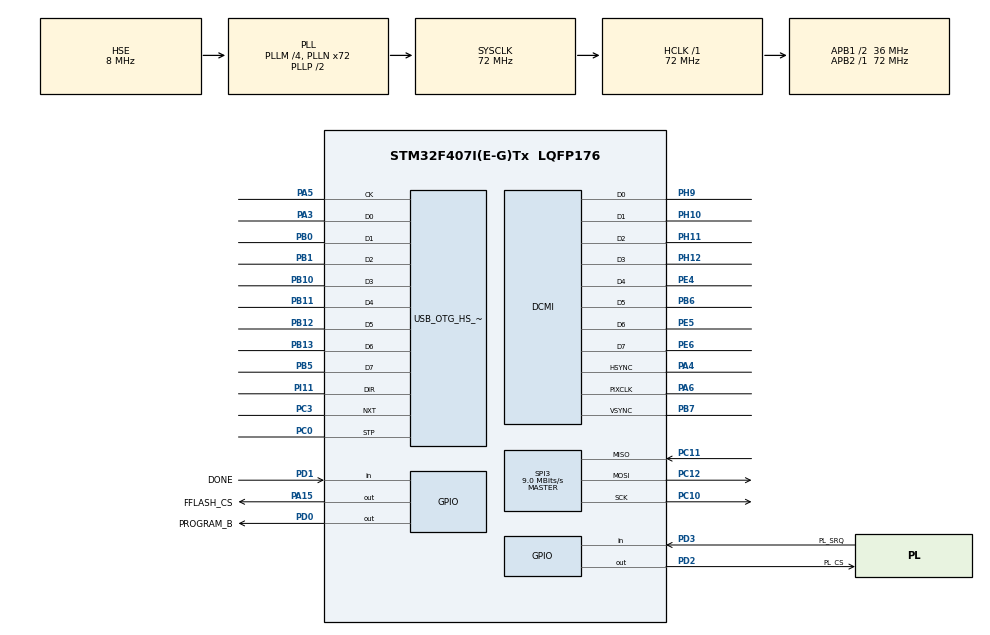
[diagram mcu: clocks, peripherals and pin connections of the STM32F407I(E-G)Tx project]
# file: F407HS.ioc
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DCMI.HSPolarity=DCMI_HSPOLARITY_HIGH
DCMI.JPEGMode=DCMI_JPEG_ENABLE
DCMI.PCKPolarity=DCMI_PCKPOLARITY_RISING
DCMI.VSPolarity=DCMI_VSPOLARITY_HIGH
Dma.DCMI.0.Direction=DMA_PERIPH_TO_MEMORY
Dma.DCMI.0.FIFOMode=DMA_FIFOMODE_DISABLE
Dma.DCMI.0.Instance=DMA2_Stream1
Dma.DCMI.0.MemDataAlignment=DMA_MDATAALIGN_WORD
Dma.DCMI.0.MemInc=DMA_MINC_ENABLE
Dma.DCMI.0.Mode=DMA_NORMAL
Dma.DCMI.0.PeriphDataAlignment=DMA_PDATAALIGN_WORD
Dma.DCMI.0.PeriphInc=DMA_PINC_DISABLE
Dma.DCMI.0.Priority=DMA_PRIORITY_LOW
Dma.Request0=DCMI
Mcu.Family=STM32F4
Mcu.Name=STM32F407I(E-G)Tx
Mcu.Package=LQFP176
NVIC.DMA2_Stream1_IRQn=true\:0\:0\:false\:false\:true\:false\:true
NVIC.OTG_HS_EP1_IN_IRQn=true\:0\:0\:false\:false\:true\:true\:true
NVIC.OTG_HS_EP1_OUT_IRQn=true\:0\:0\:false\:false\:true\:true\:true
NVIC.OTG_HS_IRQn=true\:0\:0\:false\:false\:true\:true\:true
NVIC.PriorityGroup=NVIC_PRIORITYGROUP_4
PA13.Mode=Serial_Wire
PA13.Signal=SYS_JTMS-SWDIO
PA14.Mode=Serial_Wire
PA14.Signal=SYS_JTCK-SWCLK
PA15.GPIO_Label=FFLASH_CS
PA15.GPIO_Speed=GPIO_SPEED_FREQ_HIGH
PA15.PinState=GPIO_PIN_SET
PA15.Signal=GPIO_Output
PA3.Mode=Device_HS
PA3.Signal=USB_OTG_HS_ULPI_D0
PA4.GPIO_PuPd=GPIO_PULLUP
PA4.GPIO_Speed=GPIO_SPEED_FREQ_HIGH
PA4.Mode=Slave_8_bits_External_Synchro
PA4.Signal=DCMI_HSYNC
PA5.Mode=Device_HS
PA5.Signal=USB_OTG_HS_ULPI_CK
PA6.GPIO_PuPd=GPIO_PULLUP
PA6.GPIO_Speed=GPIO_SPEED_FREQ_HIGH
PA6.Mode=Slave_8_bits_External_Synchro
PA6.Signal=DCMI_PIXCLK
PB0.Mode=Device_HS
PB0.Signal=USB_OTG_HS_ULPI_D1
PB1.Mode=Device_HS
PB1.Signal=USB_OTG_HS_ULPI_D2
PB10.Mode=Device_HS
PB10.Signal=USB_OTG_HS_ULPI_D3
PB11.Mode=Device_HS
PB11.Signal=USB_OTG_HS_ULPI_D4
PB12.Mode=Device_HS
PB12.Signal=USB_OTG_HS_ULPI_D5
PB13.Mode=Device_HS
PB13.Signal=USB_OTG_HS_ULPI_D6
PB5.Mode=Device_HS
PB5.Signal=USB_OTG_HS_ULPI_D7
PB6.GPIO_Speed=GPIO_SPEED_FREQ_HIGH
PB6.Mode=Slave_8_bits_External_Synchro
PB6.Signal=DCMI_D5
PB7.GPIO_PuPd=GPIO_PULLUP
PB7.GPIO_Speed=GPIO_SPEED_FREQ_HIGH
PB7.Mode=Slave_8_bits_External_Synchro
PB7.Signal=DCMI_VSYNC
PC0.Mode=Device_HS
PC0.Signal=USB_OTG_HS_ULPI_STP
PC10.Mode=Full_Duplex_Master
PC10.Signal=SPI3_SCK
PC11.Mode=Full_Duplex_Master
PC11.Signal=SPI3_MISO
PC12.Mode=Full_Duplex_Master
PC12.Signal=SPI3_MOSI
PC3.Mode=Device_HS
PC3.Signal=USB_OTG_HS_ULPI_NXT
PD0.GPIO_Label=PROGRAM_B
PD0.PinState=GPIO_PIN_RESET
PD0.Signal=GPIO_Output
PD1.GPIO_Label=DONE
PD1.GPIO_PuPd=GPIO_PULLDOWN
PD1.Signal=GPIO_Input
PD2.GPIO_Label=PL_CS
PD2.GPIO_Speed=GPIO_SPEED_FREQ_HIGH
PD2.PinState=GPIO_PIN_SET
PD2.Signal=GPIO_Output
PD3.GPIO_Label=PL_SRQ
PD3.GPIO_PuPd=GPIO_PULLUP
PD3.Signal=GPIO_Input
PE4.GPIO_Speed=GPIO_SPEED_FREQ_HIGH
PE4.Mode=Slave_8_bits_External_Synchro
PE4.Signal=DCMI_D4
PE5.GPIO_Speed=GPIO_SPEED_FREQ_HIGH
PE5.Mode=Slave_8_bits_External_Synchro
PE5.Signal=DCMI_D6
PE6.GPIO_Speed=GPIO_SPEED_FREQ_HIGH
PE6.Mode=Slave_8_bits_External_Synchro
PE6.Signal=DCMI_D7
PH0-OSC_IN.Mode=HSE-External-Oscillator
PH0-OSC_IN.Signal=RCC_OSC_IN
PH1-OSC_OUT.Mode=HSE-External-Oscillator
PH1-OSC_OUT.Signal=RCC_OSC_OUT
PH10.GPIO_Speed=GPIO_SPEED_FREQ_HIGH
PH10.Mode=Slave_8_bits_External_Synchro
PH10.Signal=DCMI_D1
PH11.GPIO_Speed=GPIO_SPEED_FREQ_HIGH
PH11.Mode=Slave_8_bits_External_Synchro
PH11.Signal=DCMI_D2
PH12.GPIO_Speed=GPIO_SPEED_FREQ_HIGH
PH12.Mode=Slave_8_bits_External_Synchro
PH12.Signal=DCMI_D3
PH9.GPIO_Speed=GPIO_SPEED_FREQ_HIGH
PH9.Mode=Slave_8_bits_External_Synchro
PH9.Signal=DCMI_D0
PI11.Mode=Device_HS
PI11.Signal=USB_OTG_HS_ULPI_DIR
ProjectManager.HeapSize=0x2000
ProjectManager.StackSize=0x400
ProjectManager.TargetToolchain=EWARM V8.32
RCC.48MHZClocksFreq_Value=48000000
RCC.AHBFreq_Value=72000000
RCC.APB1CLKDivider=RCC_HCLK_DIV2
RCC.APB1Freq_Value=36000000
RCC.APB1TimFreq_Value=72000000
RCC.APB2Freq_Value=72000000
RCC.APB2TimFreq_Value=72000000
RCC.CortexFreq_Value=72000000
RCC.HCLKFreq_Value=72000000
RCC.HSE_VALUE=8000000
RCC.HSI_VALUE=16000000
RCC.LSE_VALUE=32768
RCC.PLLM=4
RCC.PLLN=72
RCC.PLLQ=3
RCC.PLLSourceVirtual=RCC_PLLSOURCE_HSE
RCC.SYSCLKFreq_VALUE=72000000
RCC.SYSCLKSource=RCC_SYSCLKSOURCE_PLLCLK
RCC.VCOOutputFreq_Value=144000000
SPI3.BaudRatePrescaler=SPI_BAUDRATEPRESCALER_4
SPI3.CalculateBaudRate=9.0 MBits/s
SPI3.Direction=SPI_DIRECTION_2LINES
SPI3.Mode=SPI_MODE_MASTER
SPI3.VirtualType=VM_MASTER
USB_DEVICE.CLASS_NAME_HS=CDC
USB_DEVICE.VirtualMode-CDC_HS=Cdc
USB_DEVICE.VirtualModeHS=Cdc_HS
USB_OTG_HS.VirtualMode-Device_HS=Device_HS
VP_USB_DEVICE_VS_USB_DEVICE_CDC_HS.Mode=CDC_HS
board=custom

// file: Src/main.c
/* USER CODE BEGIN Header */
/**
  ******************************************************************************
  * @file           : main.c
  * @brief          : Main program body
  ******************************************************************************
  * @attention
  *
  * <h2><center>&copy; Copyright (c) 2020 STMicroelectronics.
  * All rights reserved.</center></h2>
  *
  * This software component is licensed by ST under Ultimate Liberty license
  * SLA0044, the "License"; You may not use this file except in compliance with
  * the License. You may obtain a copy of the License at:
  *                             www.st.com/SLA0044
  *
  ******************************************************************************
  */
/* USER CODE END Header */

#include "main.h"
#include "usb_device.h"

/* USER CODE BEGIN Includes */
#include "usb_tmc.h"
/* USER CODE END Includes */

DCMI_HandleTypeDef hdcmi;
DMA_HandleTypeDef hdma_dcmi;

SPI_HandleTypeDef hspi3;

void SystemClock_Config(void);
static void MX_GPIO_Init(void);
static void MX_SPI3_Init(void);
static void MX_DMA_Init(void);
static void MX_DCMI_Init(void);

int main(void)
{

  /* MCU Configuration--------------------------------------------------------*/

  /* Reset of all peripherals, Initializes the Flash interface and the Systick. */
  HAL_Init();

  /* Configure the system clock */
  SystemClock_Config();

  /* USER CODE BEGIN SysInit */
  USB_TMC_init();
  /* USER CODE END SysInit */

  /* Initialize all configured peripherals */
  MX_GPIO_Init();
  MX_USB_DEVICE_Init();
  MX_SPI3_Init();
  MX_DMA_Init();
  MX_DCMI_Init();

  /* Infinite loop */
  while (1)
  {

    /* USER CODE BEGIN 3 */
    USB_TMC_Process();
  }
  /* USER CODE END 3 */
}

void SystemClock_Config(void)
{
  RCC_OscInitTypeDef RCC_OscInitStruct = {0};
  RCC_ClkInitTypeDef RCC_ClkInitStruct = {0};

  /** Configure the main internal regulator output voltage
  */
  __HAL_RCC_PWR_CLK_ENABLE();
  __HAL_PWR_VOLTAGESCALING_CONFIG(PWR_REGULATOR_VOLTAGE_SCALE1);
  /** Initializes the CPU, AHB and APB busses clocks
  */
  RCC_OscInitStruct.OscillatorType = RCC_OSCILLATORTYPE_HSE;
  RCC_OscInitStruct.HSEState = RCC_HSE_ON;
  RCC_OscInitStruct.PLL.PLLState = RCC_PLL_ON;
  RCC_OscInitStruct.PLL.PLLSource = RCC_PLLSOURCE_HSE;
  RCC_OscInitStruct.PLL.PLLM = 4;
  RCC_OscInitStruct.PLL.PLLN = 72;
  RCC_OscInitStruct.PLL.PLLP = RCC_PLLP_DIV2;
  RCC_OscInitStruct.PLL.PLLQ = 3;
  if (HAL_RCC_OscConfig(&RCC_OscInitStruct) != HAL_OK)
  {
    Error_Handler();
  }
  /** Initializes the CPU, AHB and APB busses clocks
  */
  RCC_ClkInitStruct.ClockType = RCC_CLOCKTYPE_HCLK|RCC_CLOCKTYPE_SYSCLK
                              |RCC_CLOCKTYPE_PCLK1|RCC_CLOCKTYPE_PCLK2;
  RCC_ClkInitStruct.SYSCLKSource = RCC_SYSCLKSOURCE_PLLCLK;
  RCC_ClkInitStruct.AHBCLKDivider = RCC_SYSCLK_DIV1;
  RCC_ClkInitStruct.APB1CLKDivider = RCC_HCLK_DIV2;
  RCC_ClkInitStruct.APB2CLKDivider = RCC_HCLK_DIV1;

  if (HAL_RCC_ClockConfig(&RCC_ClkInitStruct, FLASH_LATENCY_2) != HAL_OK)
  {
    Error_Handler();
  }
}

static void MX_DCMI_Init(void)
{

  hdcmi.Instance = DCMI;
  hdcmi.Init.SynchroMode = DCMI_SYNCHRO_HARDWARE;
  hdcmi.Init.PCKPolarity = DCMI_PCKPOLARITY_RISING;
  hdcmi.Init.VSPolarity = DCMI_VSPOLARITY_HIGH;
  hdcmi.Init.HSPolarity = DCMI_HSPOLARITY_HIGH;
  hdcmi.Init.CaptureRate = DCMI_CR_ALL_FRAME;
  hdcmi.Init.ExtendedDataMode = DCMI_EXTEND_DATA_8B;
  hdcmi.Init.JPEGMode = DCMI_JPEG_ENABLE;
  if (HAL_DCMI_Init(&hdcmi) != HAL_OK)
  {
    Error_Handler();
  }

}

static void MX_SPI3_Init(void)
{

  /* SPI3 parameter configuration*/
  hspi3.Instance = SPI3;
  hspi3.Init.Mode = SPI_MODE_MASTER;
  hspi3.Init.Direction = SPI_DIRECTION_2LINES;
  hspi3.Init.DataSize = SPI_DATASIZE_8BIT;
  hspi3.Init.CLKPolarity = SPI_POLARITY_LOW;
  hspi3.Init.CLKPhase = SPI_PHASE_1EDGE;
  hspi3.Init.NSS = SPI_NSS_SOFT;
  hspi3.Init.BaudRatePrescaler = SPI_BAUDRATEPRESCALER_4;
  hspi3.Init.FirstBit = SPI_FIRSTBIT_MSB;
  hspi3.Init.TIMode = SPI_TIMODE_DISABLE;
  hspi3.Init.CRCCalculation = SPI_CRCCALCULATION_DISABLE;
  hspi3.Init.CRCPolynomial = 10;
  if (HAL_SPI_Init(&hspi3) != HAL_OK)
  {
    Error_Handler();
  }

}

static void MX_DMA_Init(void)
{

  /* DMA controller clock enable */
  __HAL_RCC_DMA2_CLK_ENABLE();

  /* DMA interrupt init */
  /* DMA2_Stream1_IRQn interrupt configuration */
  HAL_NVIC_SetPriority(DMA2_Stream1_IRQn, 0, 0);
  HAL_NVIC_EnableIRQ(DMA2_Stream1_IRQn);

}

static void MX_GPIO_Init(void)
{
  GPIO_InitTypeDef GPIO_InitStruct = {0};

  /* GPIO Ports Clock Enable */
  __HAL_RCC_GPIOE_CLK_ENABLE();
  __HAL_RCC_GPIOI_CLK_ENABLE();
  __HAL_RCC_GPIOH_CLK_ENABLE();
  __HAL_RCC_GPIOC_CLK_ENABLE();
  __HAL_RCC_GPIOA_CLK_ENABLE();
  __HAL_RCC_GPIOB_CLK_ENABLE();
  __HAL_RCC_GPIOD_CLK_ENABLE();

  /*Configure GPIO pin Output Level */
  HAL_GPIO_WritePin(FFLASH_CS_GPIO_Port, FFLASH_CS_Pin, GPIO_PIN_SET);

  /*Configure GPIO pin Output Level */
  HAL_GPIO_WritePin(GPIOD, PROGRAM_B_Pin|PL_CS_Pin, GPIO_PIN_SET);

  /*Configure GPIO pin : FFLASH_CS_Pin */
  GPIO_InitStruct.Pin = FFLASH_CS_Pin;
  GPIO_InitStruct.Mode = GPIO_MODE_OUTPUT_PP;
  GPIO_InitStruct.Pull = GPIO_NOPULL;
  GPIO_InitStruct.Speed = GPIO_SPEED_FREQ_HIGH;
  HAL_GPIO_Init(FFLASH_CS_GPIO_Port, &GPIO_InitStruct);

  /*Configure GPIO pin : PROGRAM_B_Pin */
  GPIO_InitStruct.Pin = PROGRAM_B_Pin;
  GPIO_InitStruct.Mode = GPIO_MODE_OUTPUT_PP;
  GPIO_InitStruct.Pull = GPIO_NOPULL;
  GPIO_InitStruct.Speed = GPIO_SPEED_FREQ_LOW;
  HAL_GPIO_Init(PROGRAM_B_GPIO_Port, &GPIO_InitStruct);

  /*Configure GPIO pin : DONE_Pin */
  GPIO_InitStruct.Pin = DONE_Pin;
  GPIO_InitStruct.Mode = GPIO_MODE_INPUT;
  GPIO_InitStruct.Pull = GPIO_PULLDOWN;
  HAL_GPIO_Init(DONE_GPIO_Port, &GPIO_InitStruct);

  /*Configure GPIO pin : PL_CS_Pin */
  GPIO_InitStruct.Pin = PL_CS_Pin;
  GPIO_InitStruct.Mode = GPIO_MODE_OUTPUT_PP;
  GPIO_InitStruct.Pull = GPIO_NOPULL;
  GPIO_InitStruct.Speed = GPIO_SPEED_FREQ_HIGH;
  HAL_GPIO_Init(PL_CS_GPIO_Port, &GPIO_InitStruct);

  /*Configure GPIO pin : PL_SRQ_Pin */
  GPIO_InitStruct.Pin = PL_SRQ_Pin;
  GPIO_InitStruct.Mode = GPIO_MODE_INPUT;
  GPIO_InitStruct.Pull = GPIO_PULLUP;
  HAL_GPIO_Init(PL_SRQ_GPIO_Port, &GPIO_InitStruct);

}

void Error_Handler(void)
{
}

/************************ (C) COPYRIGHT STMicroelectronics *****END OF FILE****/
